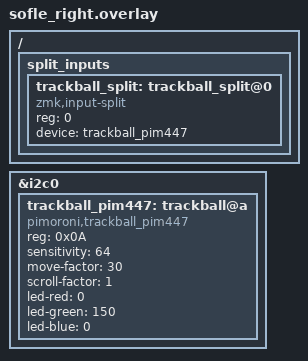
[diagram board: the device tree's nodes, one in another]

&i2c0 {
    status = "okay";

    trackball_pim447: trackball@a {
        compatible = "pimoroni,trackball_pim447";
        reg = <0x0A>;

        sensitivity = <64>;
        move-factor = <30>;
        scroll-factor = <1>;

        led-red = <0>;
        led-green = <150>;
        led-blue = <0>;
    };
};

/ {
    split_inputs {
        #address-cells = <1>;
        #size-cells = <0>;

        trackball_split: trackball_split@0 {
            compatible = "zmk,input-split";
            reg = <0>;
            device = <&trackball_pim447>;
        };
    };
};
